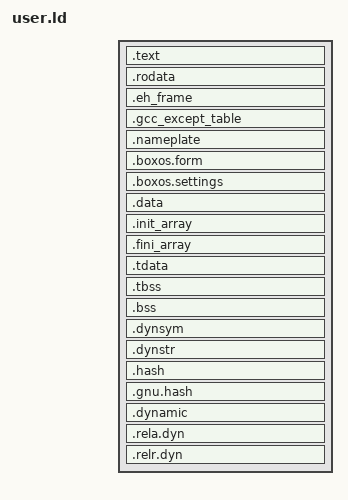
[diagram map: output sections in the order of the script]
OUTPUT_FORMAT(elf64-x86-64)
OUTPUT_ARCH(i386:x86-64)
ENTRY(_start)

/* A program is linked at 0, position-independent, and made a box the kernel
 * places where it chooses: every address in it is the place from the base.
 * shell.bin, raw code the kernel runs from its first byte at the code start,
 * is linked there instead (its Makefile: --defsym=USER_BASE=0xC000). */
USER_BASE = DEFINED(USER_BASE) ? USER_BASE : 0x0;

/* Three segments, each with one set of rights, and the thread template. Code
 * alone is executable; what is only read — constants, the unwinder's tables,
 * the Nameplate, the Form, the settings — is not, and lies on pages of its
 * own; tools/pack makes each segment the part of its kind (code, const,
 * data), the Nameplate, the Form and the settings parts of their own. */
PHDRS
{
    text   PT_LOAD FLAGS(5);   /* R+X */
    rodata PT_LOAD FLAGS(4);   /* R   */
    data   PT_LOAD FLAGS(6);   /* R+W */
    tls    PT_TLS  FLAGS(4);
    linker PT_LOAD FLAGS(0);   /* no rights, no part of the program: see the end of SECTIONS */
}

SECTIONS
{
    . = USER_BASE;

    .text : ALIGN(4096)
    {
        *boxlib_start.o(.text)     /* entry point MUST be first for flat binary loading */
        *(.text .text.*)
    } :text

    /* Each segment starts on a page of its own even when the sections that
     * open it are empty: the location moves, not only a section's start. */
    . = ALIGN(4096);

    /* Constants that hold addresses (.data.rel.ro, what the compiler makes of
     * them in position-independent code) are constants still: the kernel
     * fixes them before it maps the box, so they are read-only like the
     * rest. Named here, before .data, whose pattern would take them. */
    .rodata : ALIGN(4096)
    {
        *(.rodata .rodata.*)
        *(.data.rel.ro .data.rel.ro.*)
    } :rodata

    /* ── C++ EH metadata (read-only, lives with .rodata) ──────────────
     * .eh_frame: DWARF CFI for the boxcxx unwinder. Bounded by
     *   __eh_frame_start/__eh_frame_end — no PT_GNU_EH_FRAME needed,
     *   the unwinder builds its own sorted FDE index at startup.
     * .gcc_except_table: LSDA exception tables referenced from CFI. */
    .eh_frame : ALIGN(8)
    {
        __eh_frame_start = .;
        KEEP(*(.eh_frame .eh_frame.*))
        __eh_frame_end = .;
    }

    .gcc_except_table : ALIGN(8)
    {
        KEEP(*(.gcc_except_table .gcc_except_table.*))
    }

    /* ── Nameplate: this image's own "address -> name" table ───────────
     * Generated by tools/nameplate from the pass-1 link and linked into
     * pass 2 (src/include/nameplate_format.h explains why the table has
     * to be inside the image at all). It sits HERE, after .text and
     * .rodata, for one reason: adding it must not move a single function,
     * or the table would name the wrong ones. It moves .data and .bss
     * instead, which it does not describe — and `nameplate verify` proves
     * that rather than trusting it.
     *
     * In an ELF image the loader maps it with the rest of the read-only
     * segment, and a program reads it between these symbols. A box carries
     * it as its part `names` and its constants end before it (tools/pack):
     * there the symbols name nothing loaded, and a program finds the part in
     * the table of what the kernel loaded (box/program_part.h). PROVIDE, so a
     * binary linked without a table still links: the two symbols collapse
     * to the same address and the lookup reports "no names". */
    .nameplate : ALIGN(8)
    {
        PROVIDE(__nameplate_start = .);
        KEEP(*(.nameplate))
        PROVIDE(__nameplate_end = .);
    }

    /* ── Form: what this program takes and gives ─────────────────────────
     * The text BOX_FORM (box/form.h) or the assembler's `takes` and `gives`
     * put in .boxos.form. It sits here for the nameplate's reason — read-only,
     * after the code, moving nothing that comes before — and last, after the
     * Nameplate. An ELF image has it mapped with the read-only segment, read
     * between these symbols; a box carries it as its part `form`, put into
     * memory at start, and not among its constants. PROVIDE: an image without
     * a Form has the two symbols at one address and reads as no Form. */
    .boxos.form : ALIGN(1)
    {
        PROVIDE(__boxos_form_start = .);
        KEEP(*(.boxos.form))
        PROVIDE(__boxos_form_end = .);
    }

    /* ── Settings: what a person can set in this program ─────────────────
     * The declaration BOX_SETTINGS (box/settings.h) or the assembler's
     * `setting` put in .boxos.settings, last, for the Form's reason. An ELF
     * image has it mapped with the read-only segment, read between these
     * symbols; a box carries it as its part `settings`, put into memory at
     * start, and not among its constants. PROVIDE: an image that declares no
     * settings has the two symbols at one address. */
    .boxos.settings : ALIGN(1)
    {
        PROVIDE(__boxos_settings_start = .);
        KEEP(*(.boxos.settings))
        PROVIDE(__boxos_settings_end = .);
    }

    . = ALIGN(4096);

    .data : ALIGN(4096)
    {
        *(.data .data.*)
    } :data

    /* ── C++ ctor/dtor arrays (writable segment — legacy .ctors input
     * sections carry the W flag; keeping them next to .text would turn
     * the code segment RWX and break W^X) ──────────────────────────────
     * Empty for pure-C binaries — the start/end symbol pairs collapse
     * and the runtime walkers fall through.
     *
     * This bare-metal GCC is built without initfini-array support and
     * emits constructors into legacy .ctors/.dtors — fold those in here
     * (SORT_BY_INIT_PRIORITY understands the inverted .ctors.NNNNN
     * priority encoding). Cross-TU order is unspecified by C++, so
     * forward execution of folded .ctors entries is conformant. With
     * -fuse-cxa-atexit, .dtors stays empty (dtors go via __cxa_atexit).
     * The runtime walks init forward and fini BACKWARD, matching the
     * Itanium C++ ABI. */
    .init_array : ALIGN(8)
    {
        __init_array_start = .;
        KEEP(*(SORT_BY_INIT_PRIORITY(.init_array.*) SORT_BY_INIT_PRIORITY(.ctors.*)))
        KEEP(*(.init_array .ctors))
        __init_array_end = .;
    }

    .fini_array : ALIGN(8)
    {
        __fini_array_start = .;
        KEEP(*(SORT_BY_INIT_PRIORITY(.fini_array.*) SORT_BY_INIT_PRIORITY(.dtors.*)))
        KEEP(*(.fini_array .dtors))
        __fini_array_end = .;
    }

    /* ── TLS template (local-exec model) ──────────────────────────────
     * PT_TLS is the template the kernel makes every strand's thread-local
     * storage from (a box carries it as its `thread` part): .tdata copied,
     * .tbss zeros after it. .tbss is NOBITS and does NOT advance the
     * location counter: its addresses describe the template, not memory. */
    .tdata :
    {
        *(.tdata .tdata.*)
    } :data :tls

    .tbss :
    {
        *(.tbss .tbss.*)
        *(.tcommon)
    } :data :tls

    .bss : ALIGN(4096)
    {
        __bss_start = .;
        *(.bss .bss.*)
        *(COMMON)
        __bss_end = .;
    } :data

    __program_end = .;

    /* What a linker writes for a dynamic linker, in a static PIE: its symbols,
     * its relocations, its table. Nothing links a program at start, so none of
     * it is any part of the program: it goes into a segment with no rights,
     * which tools/pack passes over — reading the relocations from the file and
     * making them the box's fixups. shell.bin, at its fixed place, has none. */
    .dynsym   : { *(.dynsym) }   :linker
    .dynstr   : { *(.dynstr) }   :linker
    .hash     : { *(.hash) }     :linker
    .gnu.hash : { *(.gnu.hash) } :linker
    .dynamic  : { *(.dynamic) }  :linker
    .rela.dyn : { *(.rela.dyn .rela.*) } :linker
    .relr.dyn : { *(.relr.dyn) } :linker

    /DISCARD/ :
    {
        *(.comment)
        *(.note*)
    }
}
